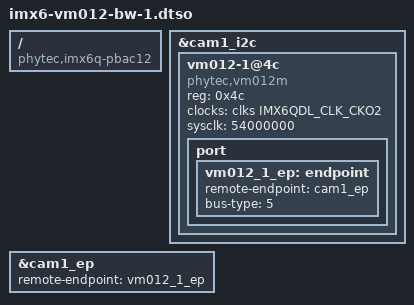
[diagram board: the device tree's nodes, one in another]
// SPDX-License-Identifier: (GPL-2.0+ OR MIT)
/*
 * Copyright (C) 2021 PHYTEC Messtechnik GmbH
 * Author: Stefan Riedmueller <s.riedmueller@phytec.de>
 */

/dts-v1/;
/plugin/;

#include <dt-bindings/clock/imx6qdl-clock.h>

/ {
	compatible = "phytec,imx6q-pbac12", "phytec,imx6dl-pbac12",
		     "phytec,imx6q-pbac06", "phytec,imx6dl-pbac06",
		     "phytec,imx6q-pbab01", "phytec,imx6dl-pbab01";
};

&cam1_i2c {
	vm012-1@4c {
		compatible = "phytec,vm012m";
		reg = <0x4c>;

		clocks = <&clks IMX6QDL_CLK_CKO2>;
		sysclk = <54000000>;

		port {
			vm012_1_ep: endpoint {
				remote-endpoint = <&cam1_ep>;
				bus-type = <5>; /* Parallel */
			};
		};
	};
};

&cam1_ep {
        remote-endpoint = <&vm012_1_ep>;
};
